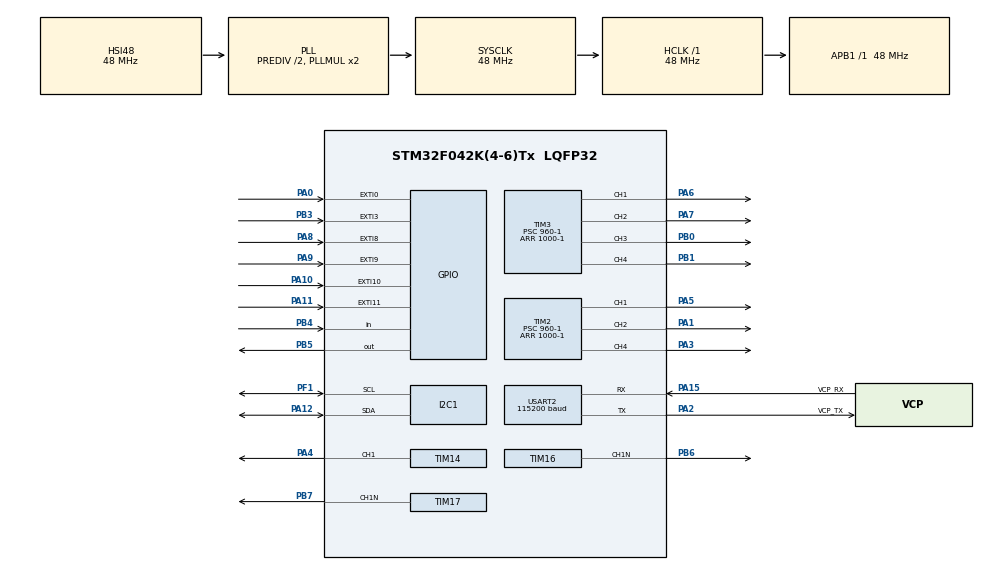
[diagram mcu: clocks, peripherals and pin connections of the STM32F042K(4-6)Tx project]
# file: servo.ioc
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Dma.Request0=USART2_RX
Dma.USART2_RX.0.Direction=DMA_PERIPH_TO_MEMORY
Dma.USART2_RX.0.Instance=DMA1_Channel5
Dma.USART2_RX.0.MemDataAlignment=DMA_MDATAALIGN_BYTE
Dma.USART2_RX.0.MemInc=DMA_MINC_ENABLE
Dma.USART2_RX.0.Mode=DMA_NORMAL
Dma.USART2_RX.0.PeriphDataAlignment=DMA_PDATAALIGN_BYTE
Dma.USART2_RX.0.PeriphInc=DMA_PINC_DISABLE
Dma.USART2_RX.0.Priority=DMA_PRIORITY_LOW
Mcu.Family=STM32F0
Mcu.Name=STM32F042K(4-6)Tx
Mcu.Package=LQFP32
NVIC.DMA1_Channel4_5_IRQn=true\:0\:0\:false\:false\:true\:false\:true\:true
NVIC.USART2_IRQn=true\:0\:0\:false\:false\:true\:true\:true\:true
PA0.Signal=GPXTI0
PA1.Signal=S_TIM2_CH2
PA10.Signal=GPXTI10
PA11.Signal=GPXTI11
PA12.Mode=I2C
PA12.Signal=I2C1_SDA
PA13.GPIO_Label=SWDIO
PA13.Mode=Serial_Wire
PA13.Signal=SYS_SWDIO
PA14.GPIO_Label=SWCLK
PA14.Mode=Serial_Wire
PA14.Signal=SYS_SWCLK
PA15.GPIO_Label=VCP_RX
PA15.Mode=Asynchronous
PA15.Signal=USART2_RX
PA2.GPIO_Label=VCP_TX
PA2.Mode=Asynchronous
PA2.Signal=USART2_TX
PA3.Signal=S_TIM2_CH4
PA4.Signal=S_TIM14_CH1
PA5.Signal=S_TIM2_CH1_ETR
PA6.Signal=S_TIM3_CH1
PA7.Signal=S_TIM3_CH2
PA8.Signal=GPXTI8
PA9.Signal=GPXTI9
PB0.Signal=S_TIM3_CH3
PB1.Signal=S_TIM3_CH4
PB3.GPIO_ModeDefaultEXTI=GPIO_MODE_IT_FALLING
PB3.Signal=GPXTI3
PB4.Signal=GPIO_Input
PB5.Signal=GPIO_Output
PB6.Mode=Output Compare1 CH1N
PB6.Signal=TIM16_CH1N
PB7.Mode=PWM Generation1 CH1N
PB7.Signal=TIM17_CH1N
PF0-OSC_IN.GPIO_Label=MCO
PF0-OSC_IN.Mode=HSE-External-Clock-Source
PF0-OSC_IN.Signal=RCC_OSC_IN
PF1-OSC_OUT.Mode=I2C
PF1-OSC_OUT.Signal=I2C1_SCL
ProjectManager.HeapSize=0x200
ProjectManager.StackSize=0x400
ProjectManager.TargetToolchain=STM32CubeIDE
RCC.AHBFreq_Value=48000000
RCC.APB1Freq_Value=48000000
RCC.APB1TimFreq_Value=48000000
RCC.HCLKFreq_Value=48000000
RCC.PLLDivider=RCC_PREDIV_DIV2
RCC.PLLSourceVirtual=RCC_PLLSOURCE_HSI48
RCC.SYSCLKFreq_VALUE=48000000
RCC.SYSCLKSource=RCC_SYSCLKSOURCE_PLLCLK
SH.S_TIM14_CH1.0=TIM14_CH1,PWM Generation1 CH1
SH.S_TIM2_CH1_ETR.0=TIM2_CH1,PWM Generation1 CH1
SH.S_TIM2_CH2.0=TIM2_CH2,PWM Generation2 CH2
SH.S_TIM2_CH4.0=TIM2_CH4,PWM Generation4 CH4
SH.S_TIM3_CH1.0=TIM3_CH1,PWM Generation1 CH1
SH.S_TIM3_CH2.0=TIM3_CH2,PWM Generation2 CH2
SH.S_TIM3_CH3.0=TIM3_CH3,PWM Generation3 CH3
SH.S_TIM3_CH4.0=TIM3_CH4,PWM Generation4 CH4
TIM14.Channel=TIM_CHANNEL_1
TIM14.Period=1000-1
TIM14.Prescaler=960-1
TIM16.Channel=TIM_CHANNEL_1
TIM16.Period=1000-1
TIM16.Prescaler=960-1
TIM17.Channel=TIM_CHANNEL_1
TIM17.Period=1000-1
TIM17.Prescaler=200-1
TIM2.Channel-PWM\ Generation1\ CH1=TIM_CHANNEL_1
TIM2.Channel-PWM\ Generation2\ CH2=TIM_CHANNEL_2
TIM2.Channel-PWM\ Generation4\ CH4=TIM_CHANNEL_4
TIM2.Period=1000-1
TIM2.Prescaler=960-1
TIM3.Channel-PWM\ Generation1\ CH1=TIM_CHANNEL_1
TIM3.Channel-PWM\ Generation2\ CH2=TIM_CHANNEL_2
TIM3.Channel-PWM\ Generation3\ CH3=TIM_CHANNEL_3
TIM3.Channel-PWM\ Generation4\ CH4=TIM_CHANNEL_4
TIM3.Period=1000-1
TIM3.Prescaler=960-1
USART2.BaudRate=115200
USART2.VirtualMode-Asynchronous=VM_ASYNC
VP_TIM14_VS_ClockSourceINT.Mode=Enable_Timer
VP_TIM16_VS_ClockSourceINT.Mode=Enable_Timer
VP_TIM17_VS_ClockSourceINT.Mode=Enable_Timer
board=NUCLEO-F042K6

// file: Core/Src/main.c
/* USER CODE BEGIN Header */
/**
  ******************************************************************************
  * @file           : main.c
  * @brief          : Main program body
  ******************************************************************************
  * @attention
  *
  * Copyright (c) 2022 STMicroelectronics.
  * All rights reserved.
  *
  * This software is licensed under terms that can be found in the LICENSE file
  * in the root directory of this software component.
  * If no LICENSE file comes with this software, it is provided AS-IS.
  *
  ******************************************************************************
  */
/* USER CODE END Header */
#include "main.h"
#include "dma.h"
#include "i2c.h"
#include "tim.h"
#include "usart.h"
#include "gpio.h"

void SystemClock_Config(void);

int main(void)
{

  /* MCU Configuration--------------------------------------------------------*/

  /* Reset of all peripherals, Initializes the Flash interface and the Systick. */
  HAL_Init();

  /* Configure the system clock */
  SystemClock_Config();

  /* Initialize all configured peripherals */
  MX_GPIO_Init();
  MX_DMA_Init();
  MX_USART2_UART_Init();
  MX_I2C1_Init();
  MX_TIM2_Init();
  MX_TIM3_Init();
  MX_TIM14_Init();
  MX_TIM16_Init();
  MX_TIM17_Init();
  /* USER CODE BEGIN 2 */
  HAL_UARTEx_ReceiveToIdle_DMA(&huart2, RxBuf, RxBuf_SIZE);
  __HAL_DMA_DISABLE_IT(&hdma_usart2_rx, DMA_IT_HT);
  /* USER CODE END 2 */

  /* Infinite loop */
  /* USER CODE BEGIN WHILE */
  printf("USART DMA Printf test\r\n");
  while (1)
  {
    /* USER CODE END WHILE */

  }
}

void SystemClock_Config(void)
{
  RCC_OscInitTypeDef RCC_OscInitStruct = {0};
  RCC_ClkInitTypeDef RCC_ClkInitStruct = {0};
  RCC_PeriphCLKInitTypeDef PeriphClkInit = {0};

  /** Initializes the RCC Oscillators according to the specified parameters
  * in the RCC_OscInitTypeDef structure.
  */
  RCC_OscInitStruct.OscillatorType = RCC_OSCILLATORTYPE_HSI|RCC_OSCILLATORTYPE_HSI48;
  RCC_OscInitStruct.HSIState = RCC_HSI_ON;
  RCC_OscInitStruct.HSI48State = RCC_HSI48_ON;
  RCC_OscInitStruct.HSICalibrationValue = RCC_HSICALIBRATION_DEFAULT;
  RCC_OscInitStruct.PLL.PLLState = RCC_PLL_ON;
  RCC_OscInitStruct.PLL.PLLSource = RCC_PLLSOURCE_HSI48;
  RCC_OscInitStruct.PLL.PLLMUL = RCC_PLL_MUL2;
  RCC_OscInitStruct.PLL.PREDIV = RCC_PREDIV_DIV2;
  if (HAL_RCC_OscConfig(&RCC_OscInitStruct) != HAL_OK)
  {
    Error_Handler();
  }

  /** Initializes the CPU, AHB and APB buses clocks
  */
  RCC_ClkInitStruct.ClockType = RCC_CLOCKTYPE_HCLK|RCC_CLOCKTYPE_SYSCLK
                              |RCC_CLOCKTYPE_PCLK1;
  RCC_ClkInitStruct.SYSCLKSource = RCC_SYSCLKSOURCE_PLLCLK;
  RCC_ClkInitStruct.AHBCLKDivider = RCC_SYSCLK_DIV1;
  RCC_ClkInitStruct.APB1CLKDivider = RCC_HCLK_DIV1;

  if (HAL_RCC_ClockConfig(&RCC_ClkInitStruct, FLASH_LATENCY_1) != HAL_OK)
  {
    Error_Handler();
  }
  PeriphClkInit.PeriphClockSelection = RCC_PERIPHCLK_I2C1;
  PeriphClkInit.I2c1ClockSelection = RCC_I2C1CLKSOURCE_HSI;
  if (HAL_RCCEx_PeriphCLKConfig(&PeriphClkInit) != HAL_OK)
  {
    Error_Handler();
  }
}

void Error_Handler(void)
{
  __disable_irq();
  while (1)
  {
  }
}
